# CS32F030x register map
File version: 1.0
Registers are 32-bit, read-write, reset 0x0 unless marked. A register's access mark holds for its fields unless they carry their own. Offsets are from the block's base; [hi:lo] are bit positions; {n}, {i} and the like mark numbered series.

## TIM14 — General-purpose-timers
Base 0x40002000
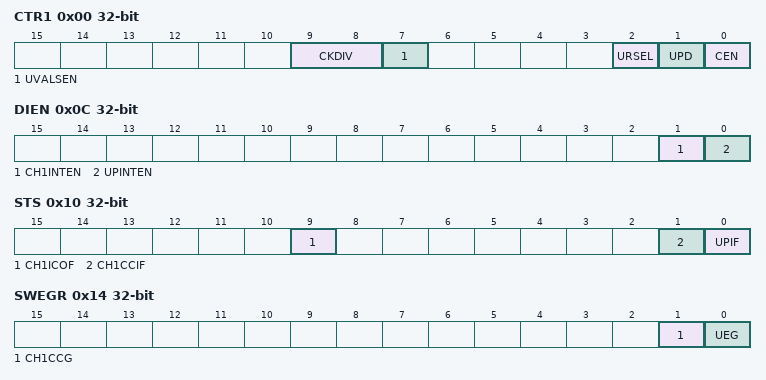
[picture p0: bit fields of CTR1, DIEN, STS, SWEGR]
0x00 CTR1 — control register 1
  [9:8] CKDIV — Clock division
  [7] UVALSEN — UVAL shadow enable
  [2] URSEL — Update request selection
  [1] UPD — Update disable
  [0] CEN — Counter enable
0x0C DIEN — DMA and interrupt enable register
  [1] CH1INTEN — Channel1 capture compare interrupt flag
  [0] UPINTEN — Enable bit for update interrupt
0x10 STS — status register
  [9] CH1ICOF — Channel 1 input capture overflow
  [1] CH1CCIF — Channel1 capture compare interrupt flag
  [0] UPIF — Enable bit for update interrupt
0x14 SWEGR wo — software event generation register
  [1] CH1CCG — Channel 1 capture compare event generation
  [0] UEG — Update event generation
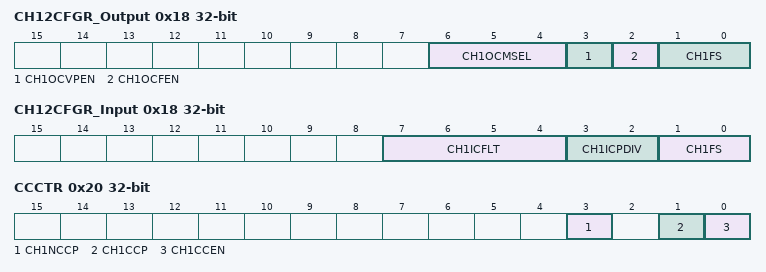
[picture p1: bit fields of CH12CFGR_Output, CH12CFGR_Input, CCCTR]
0x18 CH12CFGR_Output — channel 1 and channel 2 configuration register(output mode)
  [6:4] CH1OCMSEL — Channel 1 output compare mode selection
  [3] CH1OCVPEN — Channel 1 output compare value preload enable
  [2] CH1OCFEN — Channel 1 output compare fast enable
  [1:0] CH1FS — Channel 1 function selection
0x18 CH12CFGR_Input (alternate view of CH12CFGR_Output) — capture/compare mode register (input mode)
  [7:4] CH1ICFLT — Channel 1 input capture filter
  [3:2] CH1ICPDIV — Channel 1 input capture pre-divide
  [1:0] CH1FS — Channel 1 function selection
0x20 CCCTR — channel capture compare control register
  [3] CH1NCCP — Channel 1 complementary capture compare Polarity
  [1] CH1CCP — Channel 1 capture compare Polarity
  [0] CH1CCEN — Channel 1 capture compare enable
0x24 CNT — counter
  [15:0] CNT — counter value
0x28 PDIV — pre-divider
  [15:0] PDIV — pre-divider value
0x2C UVAL — counter update register
  [15:0] UVAL — Counter update value
0x34 CH1CCVAL — channel 1 capture compare value register
  [15:0] CH1CCVAL — Channel 1 capture compare value
0x50 REMAP
  [1:0] CH1IS — Channel 1 input selection

## EXTI — External interrupt/event controller
Base 0x40010400
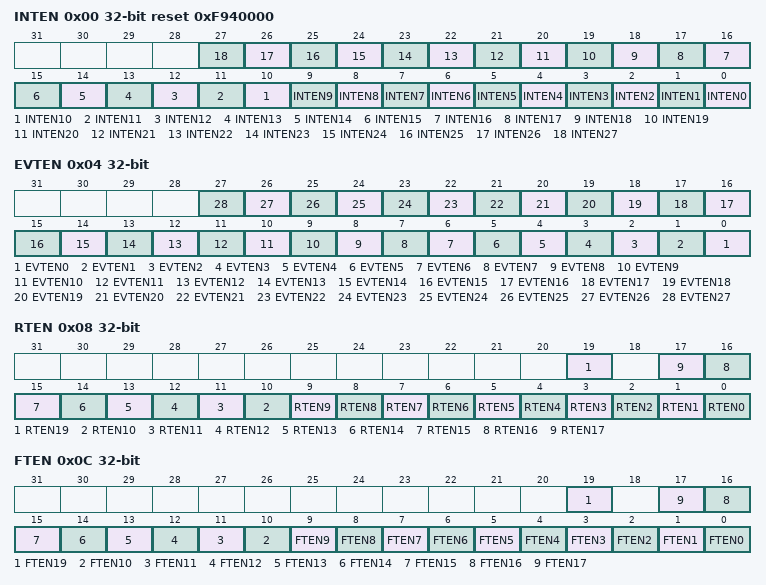
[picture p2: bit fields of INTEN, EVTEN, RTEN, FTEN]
0x00 INTEN reset 0xF940000 — Interrupt enable register
  [n] INTEN{n} (n=0..27) — Interrupt enable for line {n}
0x04 EVTEN — Event enable register
  [n] EVTEN{n} (n=0..27) — Event enable for line {n}
0x08 RTEN — Rising edge trigger enable register
  [19] RTEN19 — Rising edge trigger enable for line 19
  [n] RTEN{n} (n=0..17) — Rising edge trigger enable for line {n}
0x0C FTEN — Falling edge trigger enable register
  [19] FTEN19 — Falling edge trigger enable for line 19
  [n] FTEN{n} (n=0..17) — Falling edge trigger enable for line {n}
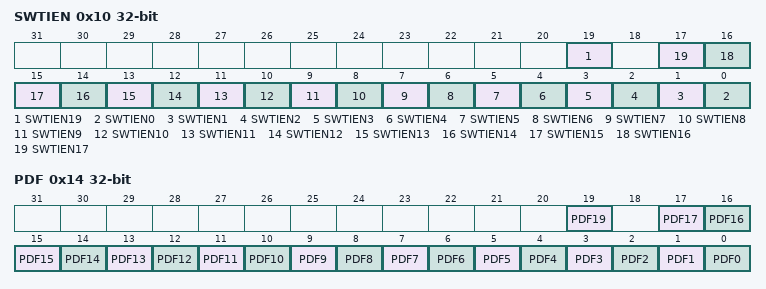
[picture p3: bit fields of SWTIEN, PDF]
0x10 SWTIEN — Software trigger interrupt/event enable register
  [19] SWTIEN19 — Software trigger interrupt/event for line 19
  [n] SWTIEN{n} (n=0..17) — Software trigger interrupt/event for line {n}
0x14 PDF — Pending flag register
  [19] PDF19 — Pending interrupt flag for line 19
  [n] PDF{n} (n=0..17) — Pending interrupt flag for line {n}

## NVIC — Nested Vectored Interrupt Controller
Base 0xE000E100
0x00 ISER — Interrupt Set Enable Register
  [31:0] SETENA
0x80 ICER — Interrupt Clear Enable Register
  [31:0] CLRENA
0x100 ISPR — Interrupt Set-Pending Register
  [31:0] SETPEND
0x180 ICPR — Interrupt Clear-Pending Register
  [31:0] CLRPEND
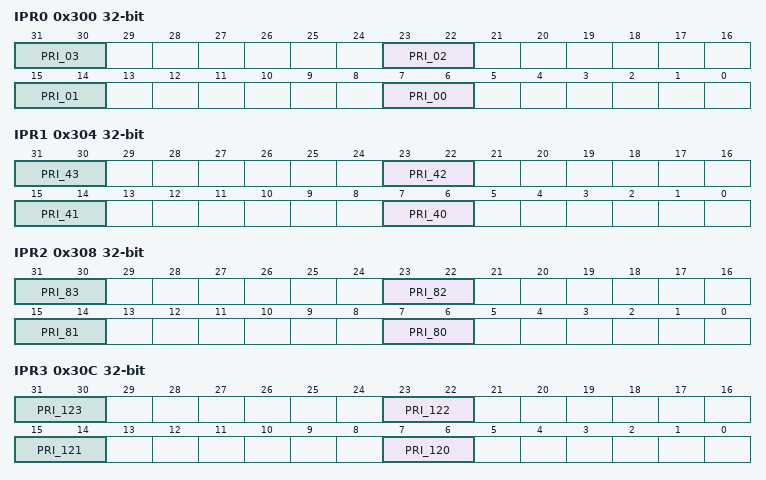
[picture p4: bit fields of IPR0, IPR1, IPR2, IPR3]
0x300 IPR0 — Interrupt Priority Register 0
  [8n+7:8n+6] PRI_{n:02} (n=0..3)
0x304 IPR1 — Interrupt Priority Register 1
  [8n-313:8n-314] PRI_{n} (n=40..43)
0x308 IPR2 — Interrupt Priority Register 2
  [8n-633:8n-634] PRI_{n} (n=80..83)
0x30C IPR3 — Interrupt Priority Register 3
  [8n-953:8n-954] PRI_{n} (n=120..123)
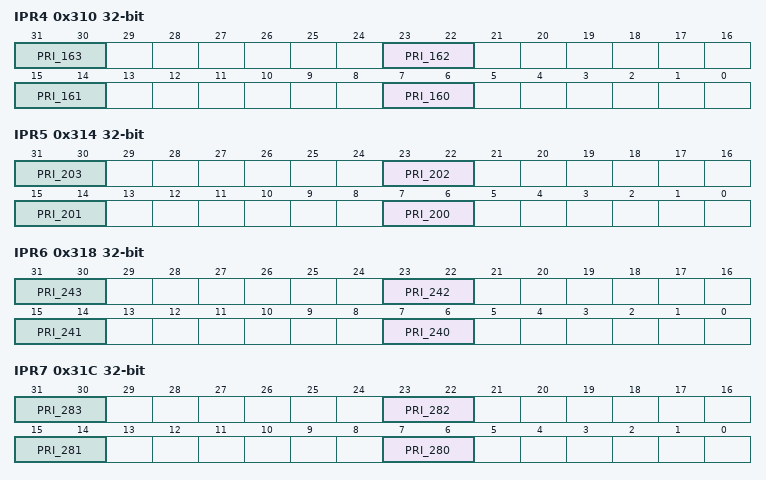
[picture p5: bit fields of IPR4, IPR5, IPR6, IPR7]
0x310 IPR4 — Interrupt Priority Register 4
  [8n-1273:8n-1274] PRI_{n} (n=160..163)
0x314 IPR5 — Interrupt Priority Register 5
  [8n-1593:8n-1594] PRI_{n} (n=200..203)
0x318 IPR6 — Interrupt Priority Register 6
  [8n-1913:8n-1914] PRI_{n} (n=240..243)
0x31C IPR7 — Interrupt Priority Register 7
  [8n-2233:8n-2234] PRI_{n} (n=280..283)
